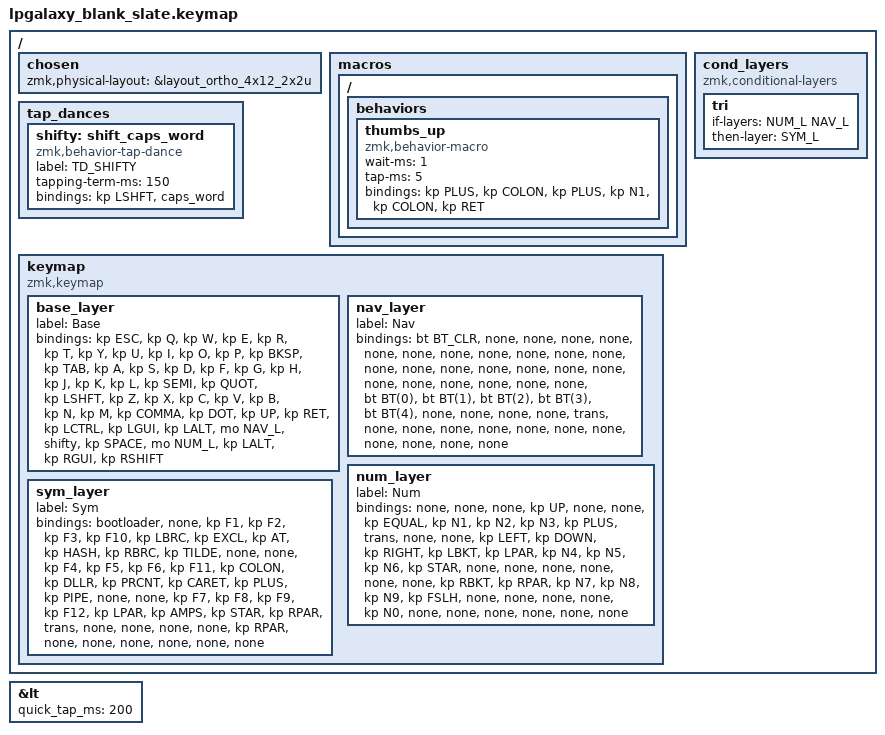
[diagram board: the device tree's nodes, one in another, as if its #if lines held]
/*
 * Copyright (c) 2022 Pete Johanson
 *
 * SPDX-License-Identifier: MIT
 */

#include <behaviors.dtsi>
#include <dt-bindings/zmk/keys.h>
#include <dt-bindings/zmk/bt.h>
#include <dt-bindings/zmk/outputs.h>

#define QWERTY_BASE 1

#define TBLE_ORTHO   1
// #define TBLE_MIT     1
// #define TBLE_DUAL_2U 1

#define NAV_L 1
#define NUM_L 2
#define SYM_L 3

// Using layer taps on thumbs, having quick tap as well helps w/ repeating space/backspace
&lt { quick_tap_ms = <200>; };

#define BT(n) BT_SEL n

/ {
    chosen {
       zmk,physical-layout =
#ifdef TBLE_DUAL_2U
                       &layout_ortho_4x12_2x2u;
#elif defined(TBLE_MIT)
                       &layout_ortho_4x12_1x2u;
#else
                       &layout_ortho_4x12_all1u;
#endif
    };

    macros {
      ZMK_MACRO(thumbs_up,
		wait-ms = <1>;
		tap-ms = <5>;
                bindings = <&kp PLUS &kp COLON &kp PLUS &kp N1 &kp COLON &kp RET>;
		)
    };
    
    tap_dances {
    	shifty: shift_caps_word {
		compatible = "zmk,behavior-tap-dance";
		label = "TD_SHIFTY";
		#binding-cells = <0>;
		tapping-term-ms = <150>;
		bindings = <&kp LSHFT>, <&caps_word>;
	};
    };

// Conditional layer only when we have less thumb keys
#ifdef TBLE_DUAL_2U
    cond_layers {
        compatible = "zmk,conditional-layers";
	tri {
	    if-layers = <NUM_L NAV_L>;
	    then-layer = <SYM_L>;
        };
    };
#endif

    keymap {
        compatible = "zmk,keymap";

        base_layer {
            label = "Base";
            bindings = <
#ifdef QWERTY_BASE
&kp ESC     &kp Q      &kp W      &kp E      &kp R      &kp T      &kp Y      &kp U      &kp I      &kp O      &kp P      &kp BKSP
&kp TAB     &kp A      &kp S      &kp D      &kp F      &kp G      &kp H      &kp J      &kp K      &kp L      &kp SEMI   &kp QUOT
&kp LSHFT   &kp Z      &kp X      &kp C      &kp V      &kp B      &kp N      &kp M      &kp COMMA  &kp DOT    &kp UP     &kp RET
#else
&kp ESC     &kp Q      &kp W      &kp F      &kp P      &kp B      &kp J      &kp L      &kp U      &kp Y      &kp QUOT   &kp BKSP
&kp TAB     &kp A      &kp R      &kp S      &kp T      &kp G      &kp M      &kp N      &kp E      &kp I      &kp O      &kp QUOT
&kp LSHFT   &kp Z      &kp X      &kp C      &kp D      &kp V      &kp K      &kp H      &kp COMMA  &kp DOT    &kp UP     &kp RET
#endif
#ifdef TBLE_DUAL_2U
&kp LCTRL   &kp LGUI   &kp LALT   &mo NAV_L   &shifty    &kp SPACE   &mo NUM_L   &kp LALT   &kp RGUI   &kp RSHIFT
#elif defined(TBLE_MIT)
&kp LCTRL   &mo NAV_L  &kp LGUI  &kp LALT    &mo NUM_L   &kp SYM_L   &mo SPACE   &kp RET    &kp LEFT   &kp DOWN   &kp RIGHT
#else
&kp LCTRL   &kp LGUI   &mo NAV_L  &kp LALT    &mo SYM_L   &mo NUM_L   &kp SPACE   &none     &kp FSLH    &kp LEFT   &kp DOWN   &kp RIGHT
#endif
            >;
        };

        nav_layer {
            label = "Nav";
            bindings = <
&bt BT_CLR &none      &none      &none      &none      &none      &none      &none      &none      &none      &none      &none
&none      &none      &none      &none      &none      &none      &none      &none      &none      &none      &none      &none
&none      &bt BT(0)  &bt BT(1)  &bt BT(2)  &bt BT(3)  &bt BT(4)  &none      &none      &none      &none      &trans     &none
#ifdef TBLE_DUAL_2U
&none      &none      &none      &none      &none      &none      &none      &none      &none      &none
#elif defined(TBLE_MIT)
&none      &none      &none      &none      &none      &none      &none      &none      &none      &none      &none
#else
&none      &none      &none      &none      &none      &none      &none      &none      &none      &trans      &trans      &trans
#endif
            >;
        };

        num_layer {
            label = "Num";
            bindings = <
&none      &none      &none      &kp UP     &none      &none      &kp EQUAL   &kp N1      &kp N2      &kp N3      &kp PLUS   &trans
&none      &none      &kp LEFT   &kp DOWN   &kp RIGHT  &kp LBKT   &kp LPAR    &kp N4      &kp N5      &kp N6      &kp STAR   &none
&none      &none      &none      &none      &none      &kp RBKT   &kp RPAR    &kp N7      &kp N8      &kp N9      &kp FSLH   &none
#ifdef TBLE_DUAL_2U
&none      &none      &none      &kp N0     &none      &none      &none      &none      &none      &none
#elif defined(TBLE_MIT)
&none      &none      &none      &kp N0     &none      &none      &kp N0     &kp DEL     &none      &none      &none
#else
&none      &none      &none      &kp N0     &none      &none      &kp N0     &none      &kp DEL     &none     &kp MINUS     &none
#endif
            >;
        };

        sym_layer {
            label = "Sym";
            bindings = <
&bootloader  &none      &kp F1     &kp F2     &kp F3     &kp F10    &kp LBRC   &kp EXCL   &kp AT     &kp HASH   &kp RBRC   &kp TILDE
&none        &none      &kp F4     &kp F5     &kp F6     &kp F11    &kp COLON  &kp DLLR   &kp PRCNT  &kp CARET  &kp PLUS   &kp PIPE
&none        &none      &kp F7     &kp F8     &kp F9     &kp F12    &kp LPAR   &kp AMPS   &kp STAR   &kp RPAR   &trans     &none
#ifdef TBLE_DUAL_2U
&none      &none      &none      &kp RPAR    &none      &none      &none      &none      &none      &none
#elif defined(TBLE_MIT)
&none      &none      &none      &kp RPAR    &none      &none      &none      &kp DEL   &none      &none      &none
#else
&none        &none      &none      &none      &none      &none      &none      &none      &kp DEL     &trans     &trans     &trans
#endif
            >;
        };


    };
};
